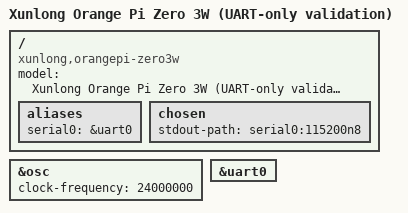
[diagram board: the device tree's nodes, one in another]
// SPDX-License-Identifier: (GPL-2.0-only OR MIT)
/dts-v1/;

#include "sun60i-a733.dtsi"

/ {
	model = "Xunlong Orange Pi Zero 3W (UART-only validation)";
	compatible = "xunlong,orangepi-zero3w", "allwinner,sun60i-a733";

	aliases {
		serial0 = &uart0;
	};

	chosen {
		stdout-path = "serial0:115200n8";
	};
};

/* A733 CCU needs a board-provided 24 MHz crystal frequency. */
&osc {
	clock-frequency = <24000000>;
};

/*
 * Existing hybrid UART output used UART0 at 0x02500000.
 * Its vendor pinctrl groups are empty; deliberately do not copy them.
 * No PB9/PB10 mux is asserted: the vendor board uses those for TWI8.
 * Boot firmware may have established the pin state, not Linux.
 */
&uart0 {
	status = "okay";
};

/*
 * MMC0, R-I2C0 and both PMICs remain disabled by the SoC DTS.
 * No 1.8V transition, regulator enable/disable, or SD-root claim.
 * RAM size and initrd location must be supplied by boot firmware.
 */
